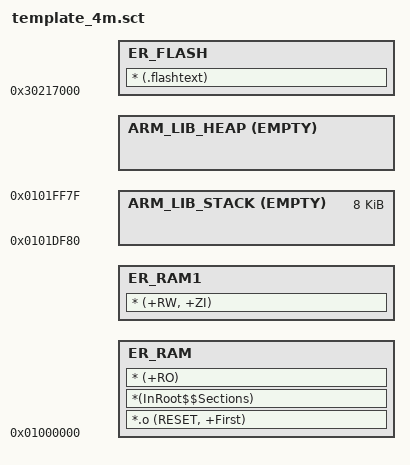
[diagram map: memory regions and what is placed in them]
; *************************************************************
; *** Scatter-Loading Description File generated by uVision ***
; *************************************************************

LR_FLASH 0x30217000 0x1BC000  {    ; load region size_region
    ER_FLASH 0x30217000  {    ; load address = execution address
        * (.flashtext)
    }
}

LR_RAM 0x01000000 0x1FF80  {    ; load region size_region
    ER_RAM 0x01000000 {    ; load address = execution address
        *.o (RESET, +First)
        *(InRoot$$Sections)
		* (+RO)
    }
}

LR_FLASH1 (ImageLimit(LR_FLASH)) 0x1BC000-(ImageLength(LR_FLASH))  {    ; load region size_region
    ER_RAM1 (ImageLimit(ER_RAM))  {    ; load address = execution address
        * (+RW, +ZI)
    }
}

LR_RAM1 (ImageLimit(LR_RAM)) 0x1FF80-(ImageLimit(LR_RAM))  {    ; load region size_region
	ARM_LIB_STACK 0x0101FF80 EMPTY -0x2000  {
    }
	ARM_LIB_HEAP (ImageLimit(ER_RAM1)) EMPTY (ImageBase(ARM_LIB_STACK)-ImageLimit(ER_RAM1))  {
    }
}

ScatterAssert((LoadLength(LR_FLASH) + LoadLength(LR_FLASH1) + LoadLength(LR_RAM)) < 0x1BC000)
